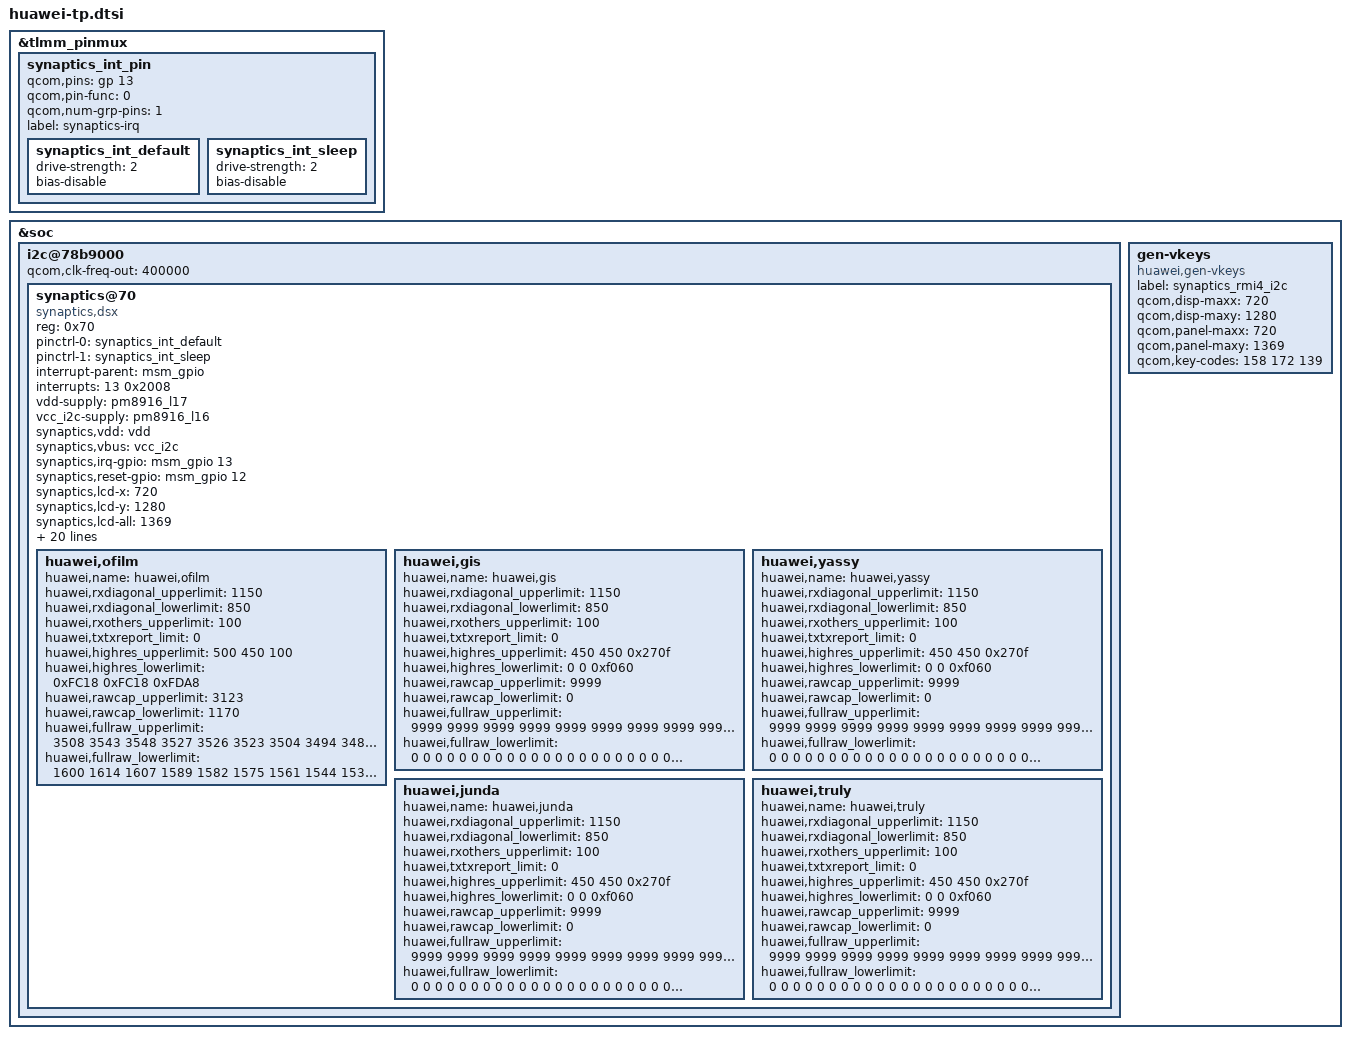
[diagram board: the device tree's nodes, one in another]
/*Add synaptics new driver "Synaptics DSX I2C V2.0"*/
/* Open holster flag */
&tlmm_pinmux {

	synaptics_int_pin {
		qcom,pins = <&gp 13>;
		qcom,pin-func = <0>;
		qcom,num-grp-pins = <1>;
		label = "synaptics-irq";
		synaptics_int_default: synaptics_int_default {
			drive-strength = <2>;
			bias-disable;
		};
		synaptics_int_sleep: synaptics_int_sleep {
			drive-strength = <2>;
			bias-disable;
		};
	};
};
&soc {
	i2c@78b9000 { /* BLSP1 QUP5 */
		status = "ok";
		#address-cells = <1>;
		#size-cells = <0>;
		qcom,clk-freq-out = <400000>;
		synaptics@70 {
			compatible = "synaptics,dsx";
			reg = <0x70>;
			pinctrl-names = "int_default","int_sleep";
			pinctrl-0 = <&synaptics_int_default>;
			pinctrl-1 = <&synaptics_int_sleep>;
			interrupt-parent = <&msm_gpio>;
			interrupts = <13 0x2008>;
			vdd-supply = <&pm8916_l17>;
			vcc_i2c-supply = <&pm8916_l16>;
			/* Some of qcom's param will not be replaced by huawei in dtb, */
			/* just ignore them:such as "pinctrl-names","pinctrl-0","pinctrl-1", */
			/* "synaptics,display-coords","synaptics,panel-coords","synaptics,i2c-pull-up", */
			/* "synaptics,power-down","synaptics,disable-gpios"*/
			synaptics,vdd = "vdd";
			synaptics,vbus = "vcc_i2c";
			synaptics,irq-gpio = <&msm_gpio 13 0x2008>;
			synaptics,reset-gpio = <&msm_gpio 12 0x0>;

			synaptics,lcd-x = <720>;
			synaptics,lcd-y = <1280>;
			synaptics,lcd-all = <1369>;
			synaptics,virtual_keys = /* KeyCode CenterX CenterY Width Height */
				/* KEY_BACK */
				<158 142 1342 150 100
				/* KEY_HOME(172) */
				172 360 1342 150 100
				/* KEY_MENU */
				139 578 1342 150 100>;

			/* SYNAPTICS_WAKE_UP_GESTURE_FLAG:'1'->enabled,'0'->disabled */
			/*IC flash is not enough for holster,so fw del one gesture*/
			synaptics,gesture_enabled = <0>;
			/* Gestures that supported:                           */
			/* bit0  Double tap                                        */
			/* bit1  Single finger slide from left to right     */
			/* bit2  Single finger slide from right to left     */
			/* bit3  Single finger slide from top to bottom  */
			/* bit4  Single finger slide from bottom to top  */
			/* bit5  Double finger slide from top to bottom--disable for holster*/
			/* bit6  Single finger slide circle                     */
			/* bit7  Single finger write letter c                  */
			/* bit8  Single finger write letter e                  */
			/* bit9  Single finger write letter m                 */
			/* bit10 Single finger write letter w                 */
			/* bit11 Palm off screen                                */
			synaptics,easy_wakeup_supported_gestures = <0xF81>;

			/*Defination of report key value  for different gestures*/
			synaptics,easy_wakeup_gesture_keys = 
			<	59 /*0.Double tap:KEY_F1*/
				60 /*1.Single finger slide from left to right*/
				61 /*2.Single finger slide from right to left:KEY_F3*/
				62 /*3.Single finger slide from top to bottom*/
				63 /*4.Single finger slide from bottom to top:KEY_F5*/
				64 /*5.Single finger slide circle clockwise*/
				65 /*6.Single finger slide circle counter-clockwise*/
				66 /*7.Single finger write letter c*/
				67 /*8.Single finger write letter e:KEY_F9*/
				68 /*9.Single finger write letter m*/
				87 /*10.Single finger write letter w:KEY_F11*/
				88 /*11.Palm off screen*/
			>;

			/* Double-tap-zone defined by huawei */
			/* Shielded area is:1cm left,1cm right,3cm up,2cm down */
			huawei,dtz_x0 = <104>;
			huawei,dtz_y0 = <423>;
			huawei,dtz_x1 = <616>;
			huawei,dtz_y1 = <1068>;

			/* SYNAPTICS_GLOVE_FUNCTION_FLAG:'1'->enabled,'0'->disabled*/
			synaptics,glove_enabled = <0>;
			/*After reduce power-consumption by exit reduce mode,*/
			/*we have to reduce f-r rate to make sure gesture work fine*/
			synaptics,fast_relax_gesture = <7>;
			/*Holster support flag*/
			synaptics,holster_supported = <1>;
			synaptics,esd_support = <1>;

			synaptics,reset-on-status = <0>;
			synaptics,power-delay-ms = <160>;
			synaptics,reset-delay-ms = <250>;
			synaptics,reset-active-ms = <10>;
			synaptics,product_name = "cherry";

			/*capacitance self-adapt*/
			/*To adjust the cutting angle threshold to the maximum range*/
			huawei,ofilm {
				huawei,name = "huawei,ofilm";
				huawei,rxdiagonal_upperlimit = <1150>;
				huawei,rxdiagonal_lowerlimit = <850>;
				huawei,rxothers_upperlimit = <100>;
				huawei,txtxreport_limit = <0>;
				huawei,highres_upperlimit = <500 450 100>;
				huawei,highres_lowerlimit = <0xFC18 0xFC18 0xFDA8>;
				huawei,rawcap_upperlimit = <3123>;
				huawei,rawcap_lowerlimit = <1170>;

				huawei,fullraw_upperlimit =
					<3508 3543 3548 3527 3526 3523 3504 3494 3482 3468 3454 3442 3422 3119 3097 3111 3066 3082 3044 3063 3024 3043 3005 3026 2916 2808 
					3397 3431 3417 3404 3388 3377 3365 3352 3340 3326 3314 3303 3279 3136 3111 3127 3085 3100 3066 3086 3049 3067 3032 3053 2944 2836 
					3386 3420 3404 3390 3374 3359 3345 3331 3317 3299 3288 3272 3250 3138 3116 3130 3089 3101 3070 3093 3053 3073 3037 3059 2952 2842 
					3383 3415 3400 3384 3366 3351 3335 3320 3305 3285 3273 3259 3236 3148 3128 3143 3101 3113 3081 3106 3066 3087 3052 3074 2967 2854 
					3369 3401 3384 3369 3350 3334 3317 3304 3285 3266 3253 3238 3214 3152 3134 3147 3109 3119 3089 3112 3072 3093 3061 3082 2976 2844 
					3360 3392 3373 3360 3339 3322 3303 3289 3272 3252 3239 3222 3196 3164 3145 3160 3122 3134 3102 3125 3089 3106 3075 3096 2991 2857 
					3356 3389 3370 3356 3335 3319 3299 3283 3267 3243 3233 3214 3187 3183 3161 3178 3143 3155 3123 3146 3112 3129 3098 3118 3015 2876 
					3349 3378 3361 3345 3325 3309 3290 3273 3254 3230 3219 3203 3174 3200 3180 3194 3160 3172 3138 3163 3131 3149 3117 3140 3034 2897 
					3336 3368 3348 3332 3313 3297 3277 3259 3243 3215 3206 3191 3159 3214 3196 3210 3176 3191 3156 3183 3150 3169 3139 3161 3052 2913 
					3336 3368 3347 3330 3309 3294 3273 3257 3240 3215 3204 3187 3157 3239 3223 3238 3204 3221 3188 3210 3178 3200 3172 3193 3085 2943 
					3327 3357 3338 3322 3302 3287 3266 3250 3231 3208 3197 3180 3148 3259 3244 3259 3230 3244 3216 3234 3205 3227 3201 3222 3112 2990 
					3323 3351 3335 3317 3297 3281 3263 3246 3226 3205 3193 3177 3144 3285 3270 3286 3259 3273 3246 3263 3239 3257 3232 3252 3143 3021 
					3324 3355 3336 3316 3298 3283 3264 3247 3229 3207 3195 3180 3146 3322 3309 3327 3301 3318 3294 3310 3286 3307 3280 3299 3191 3075 
					3318 3338 3320 3301 3281 3266 3245 3228 3206 3183 3169 3155 3116 3562 3531 3542 3493 3511 3491 3486 3467 3481 3449 3464 3352 3239>;

				huawei,fullraw_lowerlimit =
					<1600 1614 1607 1589 1582 1575 1561 1544 1530 1521 1509 1490 1479 1325 1301 1299 1283 1268 1230 1253 1238 1242 1218 1185 1180 1177 
					1555 1564 1551 1538 1525 1509 1501 1484 1470 1460 1449 1432 1423 1339 1316 1316 1267 1214 1213 1280 1256 1262 1218 1169 1191 1184 
					1548 1555 1544 1529 1518 1500 1491 1474 1458 1448 1435 1418 1405 1341 1318 1318 1214 1198 1174 1279 1261 1266 1240 1204 1224 1254 
					1543 1551 1533 1520 1509 1496 1484 1467 1453 1440 1421 1411 1397 1346 1325 1286 1198 1202 1178 1288 1264 1272 1250 1211 1252 1250 
					1536 1543 1530 1516 1502 1488 1478 1460 1444 1432 1416 1404 1389 1353 1333 1294 1208 1210 1231 1292 1275 1282 1257 1215 1262 1242 
					1533 1539 1526 1510 1496 1484 1471 1455 1439 1426 1411 1397 1378 1356 1337 1339 1299 1305 1288 1296 1278 1285 1264 1225 1267 1253 
					1527 1539 1519 1504 1490 1477 1465 1446 1429 1416 1400 1386 1365 1362 1341 1346 1321 1325 1297 1300 1283 1292 1269 1229 1273 1311 
					1524 1533 1517 1500 1484 1472 1460 1439 1425 1410 1395 1375 1355 1369 1348 1353 1327 1332 1306 1305 1292 1299 1281 1241 1279 1314 
					1519 1528 1512 1494 1478 1469 1451 1432 1420 1402 1387 1374 1354 1379 1361 1364 1342 1345 1316 1320 1302 1313 1291 1254 1293 1281 
					1519 1529 1512 1495 1480 1465 1450 1430 1415 1400 1383 1363 1344 1388 1369 1372 1348 1352 1328 1327 1314 1325 1304 1264 1299 1283 
					1514 1523 1505 1489 1475 1461 1447 1427 1411 1394 1378 1362 1341 1400 1379 1383 1360 1363 1341 1341 1323 1298 1288 1274 1310 1311 
					1512 1520 1503 1487 1471 1458 1443 1422 1407 1390 1375 1357 1334 1407 1388 1392 1370 1370 1350 1350 1291 1222 1213 1295 1320 1389 
					1511 1521 1503 1488 1471 1458 1441 1423 1404 1390 1371 1353 1328 1423 1400 1409 1386 1384 1367 1368 1304 1236 1225 1274 1336 1337 
					1516 1518 1502 1482 1464 1451 1432 1410 1395 1378 1358 1338 1313 1508 1490 1491 1457 1461 1433 1433 1418 1319 1290 1338 1379 1388>;
			};
			huawei,gis {
				huawei,name = "huawei,gis";
				huawei,rxdiagonal_upperlimit = <1150>;
				huawei,rxdiagonal_lowerlimit = <850>;
				huawei,rxothers_upperlimit = <100>;
				huawei,txtxreport_limit = <0>;
				huawei,highres_upperlimit = <450 450 0x270f>;/*0x270f==9999*/
				huawei,highres_lowerlimit = <0 0 0xf060>;/*0xf060==-4000*/
				huawei,rawcap_upperlimit = <9999>;
				huawei,rawcap_lowerlimit = <0>;

				huawei,fullraw_upperlimit =
					<9999 9999 9999 9999 9999 9999 9999 9999 9999 9999 9999 9999 9999 9999 9999 9999 9999 9999 9999 9999 9999 9999 9999 9999 
					9999 9999 9999 9999 9999 9999 9999 9999 9999 9999 9999 9999 9999 9999 9999 9999 9999 9999 9999 9999 9999 9999 9999 9999 
					9999 9999 9999 9999 9999 9999 9999 9999 9999 9999 9999 9999 9999 9999 9999 9999 9999 9999 9999 9999 9999 9999 9999 9999 
					9999 9999 9999 9999 9999 9999 9999 9999 9999 9999 9999 9999 9999 9999 9999 9999 9999 9999 9999 9999 9999 9999 9999 9999 
					9999 9999 9999 9999 9999 9999 9999 9999 9999 9999 9999 9999 9999 9999 9999 9999 9999 9999 9999 9999 9999 9999 9999 9999 
					9999 9999 9999 9999 9999 9999 9999 9999 9999 9999 9999 9999 9999 9999 9999 9999 9999 9999 9999 9999 9999 9999 9999 9999 
					9999 9999 9999 9999 9999 9999 9999 9999 9999 9999 9999 9999 9999 9999 9999 9999 9999 9999 9999 9999 9999 9999 9999 9999 
					9999 9999 9999 9999 9999 9999 9999 9999 9999 9999 9999 9999 9999 9999 9999 9999 9999 9999 9999 9999 9999 9999 9999 9999 
					9999 9999 9999 9999 9999 9999 9999 9999 9999 9999 9999 9999 9999 9999 9999 9999 9999 9999 9999 9999 9999 9999 9999 9999 
					9999 9999 9999 9999 9999 9999 9999 9999 9999 9999 9999 9999 9999 9999 9999 9999 9999 9999 9999 9999 9999 9999 9999 9999 
					9999 9999 9999 9999 9999 9999 9999 9999 9999 9999 9999 9999 9999 9999 9999 9999 9999 9999 9999 9999 9999 9999 9999 9999 
					9999 9999 9999 9999 9999 9999 9999 9999 9999 9999 9999 9999 9999 9999 9999 9999 9999 9999 9999 9999 9999 9999 9999 9999 
					9999 9999 9999 9999 9999 9999 9999 9999 9999 9999 9999 9999 9999 9999 9999 9999 9999 9999 9999 9999 9999 9999 9999 9999>;

				huawei,fullraw_lowerlimit =
					<0 0 0 0 0 0 0 0 0 0 0 0 0 0 0 0 0 0 0 0 0 0 0 0 
					0 0 0 0 0 0 0 0 0 0 0 0 0 0 0 0 0 0 0 0 0 0 0 0 
					0 0 0 0 0 0 0 0 0 0 0 0 0 0 0 0 0 0 0 0 0 0 0 0 
					0 0 0 0 0 0 0 0 0 0 0 0 0 0 0 0 0 0 0 0 0 0 0 0 
					0 0 0 0 0 0 0 0 0 0 0 0 0 0 0 0 0 0 0 0 0 0 0 0 
					0 0 0 0 0 0 0 0 0 0 0 0 0 0 0 0 0 0 0 0 0 0 0 0 
					0 0 0 0 0 0 0 0 0 0 0 0 0 0 0 0 0 0 0 0 0 0 0 0 
					0 0 0 0 0 0 0 0 0 0 0 0 0 0 0 0 0 0 0 0 0 0 0 0 
					0 0 0 0 0 0 0 0 0 0 0 0 0 0 0 0 0 0 0 0 0 0 0 0 
					0 0 0 0 0 0 0 0 0 0 0 0 0 0 0 0 0 0 0 0 0 0 0 0  
					0 0 0 0 0 0 0 0 0 0 0 0 0 0 0 0 0 0 0 0 0 0 0 0 
					0 0 0 0 0 0 0 0 0 0 0 0 0 0 0 0 0 0 0 0 0 0 0 0 
					0 0 0 0 0 0 0 0 0 0 0 0 0 0 0 0 0 0 0 0 0 0 0 0>;
			};
			huawei,yassy {
				huawei,name = "huawei,yassy";
				huawei,rxdiagonal_upperlimit = <1150>;
				huawei,rxdiagonal_lowerlimit = <850>;
				huawei,rxothers_upperlimit = <100>;
				huawei,txtxreport_limit = <0>;
				huawei,highres_upperlimit = <450 450 0x270f>;/*0x270f==9999*/
				huawei,highres_lowerlimit = <0 0 0xf060>;/*0xf060==-4000*/
				huawei,rawcap_upperlimit = <9999>;
				huawei,rawcap_lowerlimit = <0>;

				huawei,fullraw_upperlimit =
					<9999 9999 9999 9999 9999 9999 9999 9999 9999 9999 9999 9999 9999 9999 9999 9999 9999 9999 9999 9999 9999 9999 9999 9999 
					9999 9999 9999 9999 9999 9999 9999 9999 9999 9999 9999 9999 9999 9999 9999 9999 9999 9999 9999 9999 9999 9999 9999 9999 
					9999 9999 9999 9999 9999 9999 9999 9999 9999 9999 9999 9999 9999 9999 9999 9999 9999 9999 9999 9999 9999 9999 9999 9999 
					9999 9999 9999 9999 9999 9999 9999 9999 9999 9999 9999 9999 9999 9999 9999 9999 9999 9999 9999 9999 9999 9999 9999 9999 
					9999 9999 9999 9999 9999 9999 9999 9999 9999 9999 9999 9999 9999 9999 9999 9999 9999 9999 9999 9999 9999 9999 9999 9999 
					9999 9999 9999 9999 9999 9999 9999 9999 9999 9999 9999 9999 9999 9999 9999 9999 9999 9999 9999 9999 9999 9999 9999 9999 
					9999 9999 9999 9999 9999 9999 9999 9999 9999 9999 9999 9999 9999 9999 9999 9999 9999 9999 9999 9999 9999 9999 9999 9999 
					9999 9999 9999 9999 9999 9999 9999 9999 9999 9999 9999 9999 9999 9999 9999 9999 9999 9999 9999 9999 9999 9999 9999 9999 
					9999 9999 9999 9999 9999 9999 9999 9999 9999 9999 9999 9999 9999 9999 9999 9999 9999 9999 9999 9999 9999 9999 9999 9999 
					9999 9999 9999 9999 9999 9999 9999 9999 9999 9999 9999 9999 9999 9999 9999 9999 9999 9999 9999 9999 9999 9999 9999 9999 
					9999 9999 9999 9999 9999 9999 9999 9999 9999 9999 9999 9999 9999 9999 9999 9999 9999 9999 9999 9999 9999 9999 9999 9999 
					9999 9999 9999 9999 9999 9999 9999 9999 9999 9999 9999 9999 9999 9999 9999 9999 9999 9999 9999 9999 9999 9999 9999 9999 
					9999 9999 9999 9999 9999 9999 9999 9999 9999 9999 9999 9999 9999 9999 9999 9999 9999 9999 9999 9999 9999 9999 9999 9999>;

				huawei,fullraw_lowerlimit =
					<0 0 0 0 0 0 0 0 0 0 0 0 0 0 0 0 0 0 0 0 0 0 0 0 
					0 0 0 0 0 0 0 0 0 0 0 0 0 0 0 0 0 0 0 0 0 0 0 0 
					0 0 0 0 0 0 0 0 0 0 0 0 0 0 0 0 0 0 0 0 0 0 0 0 
					0 0 0 0 0 0 0 0 0 0 0 0 0 0 0 0 0 0 0 0 0 0 0 0 
					0 0 0 0 0 0 0 0 0 0 0 0 0 0 0 0 0 0 0 0 0 0 0 0 
					0 0 0 0 0 0 0 0 0 0 0 0 0 0 0 0 0 0 0 0 0 0 0 0 
					0 0 0 0 0 0 0 0 0 0 0 0 0 0 0 0 0 0 0 0 0 0 0 0 
					0 0 0 0 0 0 0 0 0 0 0 0 0 0 0 0 0 0 0 0 0 0 0 0 
					0 0 0 0 0 0 0 0 0 0 0 0 0 0 0 0 0 0 0 0 0 0 0 0 
					0 0 0 0 0 0 0 0 0 0 0 0 0 0 0 0 0 0 0 0 0 0 0 0  
					0 0 0 0 0 0 0 0 0 0 0 0 0 0 0 0 0 0 0 0 0 0 0 0 
					0 0 0 0 0 0 0 0 0 0 0 0 0 0 0 0 0 0 0 0 0 0 0 0 
					0 0 0 0 0 0 0 0 0 0 0 0 0 0 0 0 0 0 0 0 0 0 0 0>;
			};
			huawei,junda {
				huawei,name = "huawei,junda";
				huawei,rxdiagonal_upperlimit = <1150>;
				huawei,rxdiagonal_lowerlimit = <850>;
				huawei,rxothers_upperlimit = <100>;
				huawei,txtxreport_limit = <0>;
				huawei,highres_upperlimit = <450 450 0x270f>;/*0x270f==9999*/
				huawei,highres_lowerlimit = <0 0 0xf060>;/*0xf060==-4000*/
				huawei,rawcap_upperlimit = <9999>;
				huawei,rawcap_lowerlimit = <0>;

				huawei,fullraw_upperlimit =
					<9999 9999 9999 9999 9999 9999 9999 9999 9999 9999 9999 9999 9999 9999 9999 9999 9999 9999 9999 9999 9999 9999 9999 9999 
					9999 9999 9999 9999 9999 9999 9999 9999 9999 9999 9999 9999 9999 9999 9999 9999 9999 9999 9999 9999 9999 9999 9999 9999 
					9999 9999 9999 9999 9999 9999 9999 9999 9999 9999 9999 9999 9999 9999 9999 9999 9999 9999 9999 9999 9999 9999 9999 9999 
					9999 9999 9999 9999 9999 9999 9999 9999 9999 9999 9999 9999 9999 9999 9999 9999 9999 9999 9999 9999 9999 9999 9999 9999 
					9999 9999 9999 9999 9999 9999 9999 9999 9999 9999 9999 9999 9999 9999 9999 9999 9999 9999 9999 9999 9999 9999 9999 9999 
					9999 9999 9999 9999 9999 9999 9999 9999 9999 9999 9999 9999 9999 9999 9999 9999 9999 9999 9999 9999 9999 9999 9999 9999 
					9999 9999 9999 9999 9999 9999 9999 9999 9999 9999 9999 9999 9999 9999 9999 9999 9999 9999 9999 9999 9999 9999 9999 9999 
					9999 9999 9999 9999 9999 9999 9999 9999 9999 9999 9999 9999 9999 9999 9999 9999 9999 9999 9999 9999 9999 9999 9999 9999 
					9999 9999 9999 9999 9999 9999 9999 9999 9999 9999 9999 9999 9999 9999 9999 9999 9999 9999 9999 9999 9999 9999 9999 9999 
					9999 9999 9999 9999 9999 9999 9999 9999 9999 9999 9999 9999 9999 9999 9999 9999 9999 9999 9999 9999 9999 9999 9999 9999 
					9999 9999 9999 9999 9999 9999 9999 9999 9999 9999 9999 9999 9999 9999 9999 9999 9999 9999 9999 9999 9999 9999 9999 9999 
					9999 9999 9999 9999 9999 9999 9999 9999 9999 9999 9999 9999 9999 9999 9999 9999 9999 9999 9999 9999 9999 9999 9999 9999 
					9999 9999 9999 9999 9999 9999 9999 9999 9999 9999 9999 9999 9999 9999 9999 9999 9999 9999 9999 9999 9999 9999 9999 9999>;

				huawei,fullraw_lowerlimit =
					<0 0 0 0 0 0 0 0 0 0 0 0 0 0 0 0 0 0 0 0 0 0 0 0 
					0 0 0 0 0 0 0 0 0 0 0 0 0 0 0 0 0 0 0 0 0 0 0 0 
					0 0 0 0 0 0 0 0 0 0 0 0 0 0 0 0 0 0 0 0 0 0 0 0 
					0 0 0 0 0 0 0 0 0 0 0 0 0 0 0 0 0 0 0 0 0 0 0 0 
					0 0 0 0 0 0 0 0 0 0 0 0 0 0 0 0 0 0 0 0 0 0 0 0 
					0 0 0 0 0 0 0 0 0 0 0 0 0 0 0 0 0 0 0 0 0 0 0 0 
					0 0 0 0 0 0 0 0 0 0 0 0 0 0 0 0 0 0 0 0 0 0 0 0 
					0 0 0 0 0 0 0 0 0 0 0 0 0 0 0 0 0 0 0 0 0 0 0 0 
					0 0 0 0 0 0 0 0 0 0 0 0 0 0 0 0 0 0 0 0 0 0 0 0 
					0 0 0 0 0 0 0 0 0 0 0 0 0 0 0 0 0 0 0 0 0 0 0 0  
					0 0 0 0 0 0 0 0 0 0 0 0 0 0 0 0 0 0 0 0 0 0 0 0 
					0 0 0 0 0 0 0 0 0 0 0 0 0 0 0 0 0 0 0 0 0 0 0 0 
					0 0 0 0 0 0 0 0 0 0 0 0 0 0 0 0 0 0 0 0 0 0 0 0>;
			};
			huawei,truly {
				huawei,name = "huawei,truly";
				huawei,rxdiagonal_upperlimit = <1150>;
				huawei,rxdiagonal_lowerlimit = <850>;
				huawei,rxothers_upperlimit = <100>;
				huawei,txtxreport_limit = <0>;
				huawei,highres_upperlimit = <450 450 0x270f>;/*0x270f==9999*/
				huawei,highres_lowerlimit = <0 0 0xf060>;/*0xf060==-4000*/
				huawei,rawcap_upperlimit = <9999>;
				huawei,rawcap_lowerlimit = <0>;

				huawei,fullraw_upperlimit =
					<9999 9999 9999 9999 9999 9999 9999 9999 9999 9999 9999 9999 9999 9999 9999 9999 9999 9999 9999 9999 9999 9999 9999 9999 
					9999 9999 9999 9999 9999 9999 9999 9999 9999 9999 9999 9999 9999 9999 9999 9999 9999 9999 9999 9999 9999 9999 9999 9999 
					9999 9999 9999 9999 9999 9999 9999 9999 9999 9999 9999 9999 9999 9999 9999 9999 9999 9999 9999 9999 9999 9999 9999 9999 
					9999 9999 9999 9999 9999 9999 9999 9999 9999 9999 9999 9999 9999 9999 9999 9999 9999 9999 9999 9999 9999 9999 9999 9999 
					9999 9999 9999 9999 9999 9999 9999 9999 9999 9999 9999 9999 9999 9999 9999 9999 9999 9999 9999 9999 9999 9999 9999 9999 
					9999 9999 9999 9999 9999 9999 9999 9999 9999 9999 9999 9999 9999 9999 9999 9999 9999 9999 9999 9999 9999 9999 9999 9999 
					9999 9999 9999 9999 9999 9999 9999 9999 9999 9999 9999 9999 9999 9999 9999 9999 9999 9999 9999 9999 9999 9999 9999 9999 
					9999 9999 9999 9999 9999 9999 9999 9999 9999 9999 9999 9999 9999 9999 9999 9999 9999 9999 9999 9999 9999 9999 9999 9999 
					9999 9999 9999 9999 9999 9999 9999 9999 9999 9999 9999 9999 9999 9999 9999 9999 9999 9999 9999 9999 9999 9999 9999 9999 
					9999 9999 9999 9999 9999 9999 9999 9999 9999 9999 9999 9999 9999 9999 9999 9999 9999 9999 9999 9999 9999 9999 9999 9999 
					9999 9999 9999 9999 9999 9999 9999 9999 9999 9999 9999 9999 9999 9999 9999 9999 9999 9999 9999 9999 9999 9999 9999 9999 
					9999 9999 9999 9999 9999 9999 9999 9999 9999 9999 9999 9999 9999 9999 9999 9999 9999 9999 9999 9999 9999 9999 9999 9999 
					9999 9999 9999 9999 9999 9999 9999 9999 9999 9999 9999 9999 9999 9999 9999 9999 9999 9999 9999 9999 9999 9999 9999 9999>;

				huawei,fullraw_lowerlimit =
					<0 0 0 0 0 0 0 0 0 0 0 0 0 0 0 0 0 0 0 0 0 0 0 0 
					0 0 0 0 0 0 0 0 0 0 0 0 0 0 0 0 0 0 0 0 0 0 0 0 
					0 0 0 0 0 0 0 0 0 0 0 0 0 0 0 0 0 0 0 0 0 0 0 0 
					0 0 0 0 0 0 0 0 0 0 0 0 0 0 0 0 0 0 0 0 0 0 0 0 
					0 0 0 0 0 0 0 0 0 0 0 0 0 0 0 0 0 0 0 0 0 0 0 0 
					0 0 0 0 0 0 0 0 0 0 0 0 0 0 0 0 0 0 0 0 0 0 0 0 
					0 0 0 0 0 0 0 0 0 0 0 0 0 0 0 0 0 0 0 0 0 0 0 0 
					0 0 0 0 0 0 0 0 0 0 0 0 0 0 0 0 0 0 0 0 0 0 0 0 
					0 0 0 0 0 0 0 0 0 0 0 0 0 0 0 0 0 0 0 0 0 0 0 0 
					0 0 0 0 0 0 0 0 0 0 0 0 0 0 0 0 0 0 0 0 0 0 0 0  
					0 0 0 0 0 0 0 0 0 0 0 0 0 0 0 0 0 0 0 0 0 0 0 0 
					0 0 0 0 0 0 0 0 0 0 0 0 0 0 0 0 0 0 0 0 0 0 0 0 
					0 0 0 0 0 0 0 0 0 0 0 0 0 0 0 0 0 0 0 0 0 0 0 0>;
			};
		};
	};
	
	/*To disable gen-vkeys.c probe,avoid generate kobject*/
	gen-vkeys {
		compatible = "huawei,gen-vkeys";
		label = "synaptics_rmi4_i2c";
		qcom,disp-maxx = <720>;
		qcom,disp-maxy = <1280>;
		qcom,panel-maxx = <720>;
		qcom,panel-maxy = <1369>;
		qcom,key-codes = <158 172 139>;
	};

};
